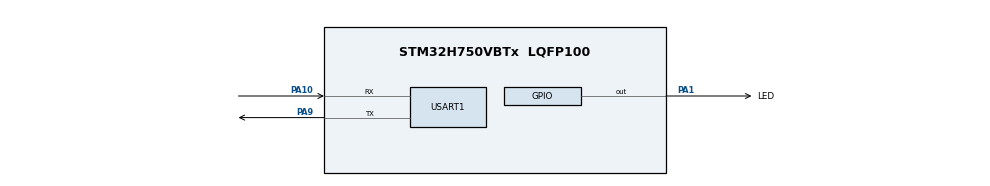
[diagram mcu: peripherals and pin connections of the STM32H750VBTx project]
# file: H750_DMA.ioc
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CORTEX_M7.AccessPermission_Spec=MPU_REGION_FULL_ACCESS
CORTEX_M7.BaseAddress_Spec=0x24000000
CORTEX_M7.CPU_DCache=Enabled
CORTEX_M7.CPU_ICache=Enabled
CORTEX_M7.DisableExec_Spec=MPU_INSTRUCTION_ACCESS_ENABLE
CORTEX_M7.Enable_S-Cortex_Memory_Protection_Unit_Region1_Settings_S=__NULL
CORTEX_M7.IsBufferable_Spec=MPU_ACCESS_NOT_BUFFERABLE
CORTEX_M7.IsCacheable_Spec=MPU_ACCESS_CACHEABLE
CORTEX_M7.IsShareable_Spec=MPU_ACCESS_SHAREABLE
CORTEX_M7.MPU_Control=__NULL
CORTEX_M7.Size_Spec=MPU_REGION_SIZE_512KB
CORTEX_M7.SubRegionDisable_Spec=0x0
CORTEX_M7.TypeExtField_Spec=MPU_TEX_LEVEL0
Dma.Request0=USART1_TX
Dma.USART1_TX.0.Direction=DMA_MEMORY_TO_PERIPH
Dma.USART1_TX.0.EventEnable=DISABLE
Dma.USART1_TX.0.FIFOMode=DMA_FIFOMODE_DISABLE
Dma.USART1_TX.0.Instance=DMA2_Stream5
Dma.USART1_TX.0.MemDataAlignment=DMA_MDATAALIGN_BYTE
Dma.USART1_TX.0.MemInc=DMA_MINC_ENABLE
Dma.USART1_TX.0.Mode=DMA_NORMAL
Dma.USART1_TX.0.PeriphDataAlignment=DMA_PDATAALIGN_BYTE
Dma.USART1_TX.0.PeriphInc=DMA_PINC_DISABLE
Dma.USART1_TX.0.Polarity=HAL_DMAMUX_REQ_GEN_RISING
Dma.USART1_TX.0.Priority=DMA_PRIORITY_MEDIUM
Dma.USART1_TX.0.RequestNumber=1
Dma.USART1_TX.0.SignalID=NONE
Dma.USART1_TX.0.SyncEnable=DISABLE
Dma.USART1_TX.0.SyncPolarity=HAL_DMAMUX_SYNC_NO_EVENT
Dma.USART1_TX.0.SyncRequestNumber=1
Dma.USART1_TX.0.SyncSignalID=NONE
Mcu.Family=STM32H7
Mcu.Name=STM32H750VBTx
Mcu.Package=LQFP100
NVIC.DMA2_Stream5_IRQn=true\:0\:0\:false\:false\:true\:false\:true\:true
NVIC.PriorityGroup=NVIC_PRIORITYGROUP_4
NVIC.USART1_IRQn=true\:0\:0\:false\:false\:true\:true\:true\:true
PA1.GPIO_Label=LED
PA1.Signal=GPIO_Output
PA10.Mode=Asynchronous
PA10.Signal=USART1_RX
PA9.Mode=Asynchronous
PA9.Signal=USART1_TX
PH0-OSC_IN\ (PH0).Mode=HSE-External-Oscillator
PH0-OSC_IN\ (PH0).Signal=RCC_OSC_IN
PH1-OSC_OUT\ (PH1).Mode=HSE-External-Oscillator
PH1-OSC_OUT\ (PH1).Signal=RCC_OSC_OUT
ProjectManager.HeapSize=0x400
ProjectManager.StackSize=0x400
ProjectManager.TargetToolchain=MDK-ARM V5
RCC.ADCFreq_Value=16125000
RCC.APB1Freq_Value=120000000
RCC.APB2Freq_Value=120000000
RCC.APB3Freq_Value=120000000
RCC.APB4Freq_Value=120000000
RCC.CortexFreq_Value=480000000
RCC.D1PPRE=RCC_APB3_DIV2
RCC.D2PPRE1=RCC_APB1_DIV2
RCC.D2PPRE2=RCC_APB2_DIV2
RCC.D3PPRE=RCC_APB4_DIV2
RCC.DIVM1=2
RCC.DIVN1=240
RCC.HCLKFreq_Value=240000000
RCC.HPRE=RCC_HCLK_DIV2
RCC.HSE_VALUE=8000000
RCC.PLLSourceVirtual=RCC_PLLSOURCE_HSE
RCC.PWR_Regulator_Voltage_Scale=PWR_REGULATOR_VOLTAGE_SCALE0
RCC.ProductRev=revV
RCC.SYSCLKFreq_VALUE=480000000
RCC.SYSCLKSource=RCC_SYSCLKSOURCE_PLLCLK
RCC.USBFreq_Value=480000000
USART1.VirtualMode-Asynchronous=VM_ASYNC
board=custom

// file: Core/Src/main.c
/* USER CODE BEGIN Header */
/**
  ******************************************************************************
  * @file           : main.c
  * @brief          : Main program body
  ******************************************************************************
  * @attention
  *
  * Copyright (c) 2023 STMicroelectronics.
  * All rights reserved.
  *
  * This software is licensed under terms that can be found in the LICENSE file
  * in the root directory of this software component.
  * If no LICENSE file comes with this software, it is provided AS-IS.
  *
  ******************************************************************************
  */
/* USER CODE END Header */
#include "main.h"
#include "dma.h"
#include "usart.h"
#include "gpio.h"

void SystemClock_Config(void);
/* USER CODE BEGIN PFP */
//unsigned char s_buf[]="hello world\r\n";

/* USER CODE END PFP */

int main(void)
{
  /* USER CODE BEGIN 1 */
//	uint8_t s_buf[4];
//	s_buf[0] = 1;
//	s_buf[1] = 2;
//	s_buf[2] = 3;
//	s_buf[3] = 4;

  /* USER CODE END 1 */

  /* Enable I-Cache---------------------------------------------------------*/
  SCB_EnableICache();

  /* Enable D-Cache---------------------------------------------------------*/
  SCB_EnableDCache();
	SCB->CACR|=1<<2; //强制 D-Cache 透写,如不开启,实际使用中可能遇到各种问题
  /* MCU Configuration--------------------------------------------------------*/

  /* Reset of all peripherals, Initializes the Flash interface and the Systick. */
  HAL_Init();

  /* Configure the system clock */
  SystemClock_Config();

  /* Initialize all configured peripherals */
  MX_GPIO_Init();
  MX_DMA_Init();
  MX_USART1_UART_Init();
  /* USER CODE BEGIN 2 */

//	unsigned char s_buf[]="hello world\r\n";
//  HAL_UART_Transmit_DMA(&huart1,s_buf,sizeof(s_buf));
	//HAL_UART_Transmit_DMA(&huart1,s_buf,2);
	uint8_t s_buf[4];
	s_buf[0] = 1;
	s_buf[1] = 2;
	s_buf[2] = 3;
	s_buf[3] = 4;
  /* USER CODE END 2 */

  /* Infinite loop */
  while (1)
  {

    /* USER CODE BEGIN 3 */
		//printf("1\r\n");
//		for(int i=0;i<sizeof(s_buf)/sizeof(uint8_t);i++)
//		{
//			printf("%d\r\n",s_buf[i]);
//		}
		HAL_UART_Transmit_DMA(&huart1,s_buf,4);
//		HAL_UART_Transmit_DMA(&huart1,s_buf,sizeof(s_buf));
//		HAL_GPIO_WritePin(LED_GPIO_Port, LED_Pin, GPIO_PIN_RESET);
//		HAL_Delay(300);
//		HAL_GPIO_WritePin(LED_GPIO_Port, LED_Pin, GPIO_PIN_SET);
//		HAL_Delay(300);
  }
  /* USER CODE END 3 */
}

void SystemClock_Config(void)
{
  RCC_OscInitTypeDef RCC_OscInitStruct = {0};
  RCC_ClkInitTypeDef RCC_ClkInitStruct = {0};

  /** Supply configuration update enable
  */
  HAL_PWREx_ConfigSupply(PWR_LDO_SUPPLY);

  /** Configure the main internal regulator output voltage
  */
  __HAL_PWR_VOLTAGESCALING_CONFIG(PWR_REGULATOR_VOLTAGE_SCALE1);

  while(!__HAL_PWR_GET_FLAG(PWR_FLAG_VOSRDY)) {}

  __HAL_RCC_SYSCFG_CLK_ENABLE();
  __HAL_PWR_VOLTAGESCALING_CONFIG(PWR_REGULATOR_VOLTAGE_SCALE0);

  while(!__HAL_PWR_GET_FLAG(PWR_FLAG_VOSRDY)) {}

  /** Initializes the RCC Oscillators according to the specified parameters
  * in the RCC_OscInitTypeDef structure.
  */
  RCC_OscInitStruct.OscillatorType = RCC_OSCILLATORTYPE_HSE;
  RCC_OscInitStruct.HSEState = RCC_HSE_ON;
  RCC_OscInitStruct.PLL.PLLState = RCC_PLL_ON;
  RCC_OscInitStruct.PLL.PLLSource = RCC_PLLSOURCE_HSE;
  RCC_OscInitStruct.PLL.PLLM = 2;
  RCC_OscInitStruct.PLL.PLLN = 240;
  RCC_OscInitStruct.PLL.PLLP = 2;
  RCC_OscInitStruct.PLL.PLLQ = 2;
  RCC_OscInitStruct.PLL.PLLR = 2;
  RCC_OscInitStruct.PLL.PLLRGE = RCC_PLL1VCIRANGE_2;
  RCC_OscInitStruct.PLL.PLLVCOSEL = RCC_PLL1VCOWIDE;
  RCC_OscInitStruct.PLL.PLLFRACN = 0;
  if (HAL_RCC_OscConfig(&RCC_OscInitStruct) != HAL_OK)
  {
    Error_Handler();
  }

  /** Initializes the CPU, AHB and APB buses clocks
  */
  RCC_ClkInitStruct.ClockType = RCC_CLOCKTYPE_HCLK|RCC_CLOCKTYPE_SYSCLK
                              |RCC_CLOCKTYPE_PCLK1|RCC_CLOCKTYPE_PCLK2
                              |RCC_CLOCKTYPE_D3PCLK1|RCC_CLOCKTYPE_D1PCLK1;
  RCC_ClkInitStruct.SYSCLKSource = RCC_SYSCLKSOURCE_PLLCLK;
  RCC_ClkInitStruct.SYSCLKDivider = RCC_SYSCLK_DIV1;
  RCC_ClkInitStruct.AHBCLKDivider = RCC_HCLK_DIV2;
  RCC_ClkInitStruct.APB3CLKDivider = RCC_APB3_DIV2;
  RCC_ClkInitStruct.APB1CLKDivider = RCC_APB1_DIV2;
  RCC_ClkInitStruct.APB2CLKDivider = RCC_APB2_DIV2;
  RCC_ClkInitStruct.APB4CLKDivider = RCC_APB4_DIV2;

  if (HAL_RCC_ClockConfig(&RCC_ClkInitStruct, FLASH_LATENCY_4) != HAL_OK)
  {
    Error_Handler();
  }
}

void Error_Handler(void)
{
  __disable_irq();
  while (1)
  {
  }
}
